# A31G33x register map
Vendor: VENDOR ABOV Semiconductor Co., Ltd.; Series: A31G33x; File version: 1.0
CPU: CM0+ r0p1, little endian, no MPU, no FPU, VTOR, 2 interrupt priority bits
Registers are 32-bit, read-only, no defined reset value unless marked. A register's access mark holds for its fields unless they carry their own. Offsets are from the block's base; [hi:lo] are bit positions; 'fields as' and 'values as' point back to an identical list.

## TIMER20 — Timer/Counter 20
Base 0x40002500
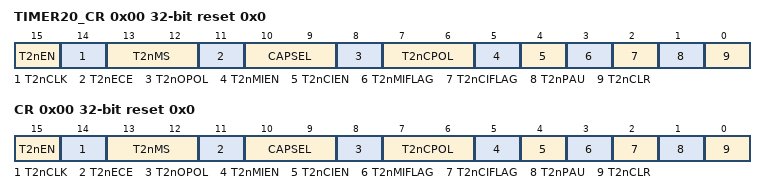
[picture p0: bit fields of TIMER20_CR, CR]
0x00 TIMER20_CR rw reset 0x0 (alternate view of CR) — TIMER2n Control Register
  [15] T2nEN — TIMER2n Operation Enable
  [14] T2nCLK — TIMER2n Clock Selection
  [13:12] T2nMS — TIMER2n Operation Mode Selection
  [11] T2nECE — TIMER2n External Clock Edge Selection
  [10:9] CAPSEL — TIMER2n Capture Signal Selection
  [8] T2nOPOL — TIMER2n Output Polarity Selection
  [7:6] T2nCPOL — TIMER2n Capture Polarity Selection
  [5] T2nMIEN — TIMER2n Match Interrupt Enable
  [4] T2nCIEN — TIMER2n Capture Interrupt Enable
  [3] T2nMIFLAG — TIMER2n Match Interrupt Flag
  [2] T2nCIFLAG — TIMER2n Capture Interrupt Flag
  [1] T2nPAU — TIMER2n Counter Temporary Pause Control
  [0] T2nCLR — TIMER2n Counter and Prescaler Clear
0x00 CR rw reset 0x0 — TIMER2n Control Register
  fields as TIMER20_CR
0x04 ADR rw reset 0xFFFFFFFF — TIMER2n A Data Register
  [31:0] ADATA — TIMER2n A Data
0x08 BDR rw reset 0xFFFFFFFF — TIMER2n B Data Register
  [31:0] BDATA — TIMER2n B Data
0x0C CAPDR reset 0x0 — TIMER2n Capture Data Register
  [31:0] CAPD — TIMER2n Capture Data
0x10 PREDR rw reset 0xFFF — TIMER2n Prescaler Data Register
  [11:0] PRED — TIMER2n Prescaler Data
0x14 CNT reset 0x0 — TIMER2n Counter Register
  [31:0] CNT — TIMER2n Counter

## TIMER21 — Timer/Counter 21
Base 0x40002600
Registers as TIMER20 (with TIMER20 read as TIMER21); these are added or differ:
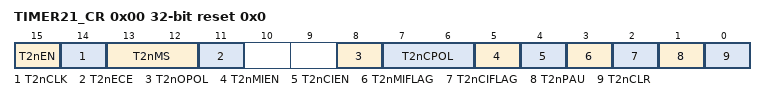
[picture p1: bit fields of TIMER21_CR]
0x00 TIMER21_CR rw reset 0x0 (alternate view of CR) — TIMER2n Control Register
  [15] T2nEN — TIMER2n Operation Enable
  [14] T2nCLK — TIMER2n Clock Selection
  [13:12] T2nMS — TIMER2n Operation Mode Selection
  [11] T2nECE — TIMER2n External Clock Edge Selection
  [8] T2nOPOL — TIMER2n Output Polarity Selection
  [7:6] T2nCPOL — TIMER2n Capture Polarity Selection
  [5] T2nMIEN — TIMER2n Match Interrupt Enable
  [4] T2nCIEN — TIMER2n Capture Interrupt Enable
  [3] T2nMIFLAG — TIMER2n Match Interrupt Flag
  [2] T2nCIFLAG — TIMER2n Capture Interrupt Flag
  [1] T2nPAU — TIMER2n Counter Temporary Pause Control
  [0] T2nCLR — TIMER2n Counter and Prescaler Clear

## SPIn
Base 0x5B000000
Same registers: SPI0 0x40005800, SPI1 0x40005880
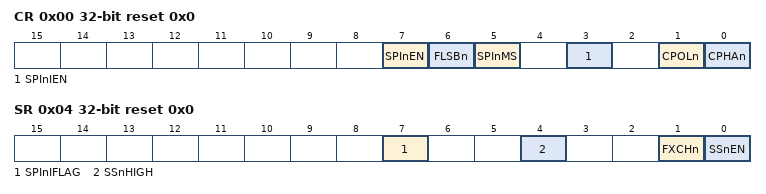
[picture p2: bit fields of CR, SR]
0x00 CR rw reset 0x0 — SPIn Control Register
  [7] SPInEN — SPIn Operation Control
    0=Disable SPIn operation; 1=Enable SPIn operation
  [6] FLSBn — Data Transmission Sequence Selection
    0=msbFirst; 1=lsbFirst
  [5] SPInMS — Master/Slave Selection
    0=Slave mode; 1=Master mode
  [3] SPInIEN — SPIn Interrupt Enable
    0=Disable SPIn interrupt; 1=Enable SPIn interrupt
  [1] CPOLn — Selects the clock polarity of SCK
    0=IdleLow (SCK to 0 when idle); 1=IdleHigh (SCK to 1 when idle)
  [0] CPHAn — The CPOLn and this bit determine if data are sampled on the leading or trailing edge of SCK
    0=StartIdle (Start with idle state.); 1=StartInverted (Start with inverted idle state.)
0x04 SR rw reset 0x0 — SPIn Status Register
  [7] SPInIFLAG — SPIn Interrupt Flag
    0=No request occurred; 1=Request occurred
  [4] SSnHIGH — This bit is set when the SSn pin goes high level during the pin is the corresponding function
    0=NoEffect; 1=High (The SSn pin has gone from low level to high)
  [1] FXCHn — SPIn Pin Function Exchange Control
    0=NoEffect; 1=Exchange MOSIn and MISOn function
  [0] SSnEN — SSn Pin Operation Control
    0=Disable SSn pin operation; 1=Enable SSn pin operation
0x08 RDR reset 0x0 — SPIn Receive Data Register
  [7:0] RDATA — SPIn Receive Data
0x0C TDR rw reset 0x0 — SPIn Transmit Data Register
  [7:0] TDATA — SPIn Transmit Data
0x10 PREDR rw reset 0x3FF — SPIn Prescaler Data Register
  [9:0] PRED — The value in this register is used to generate an SCK clock
